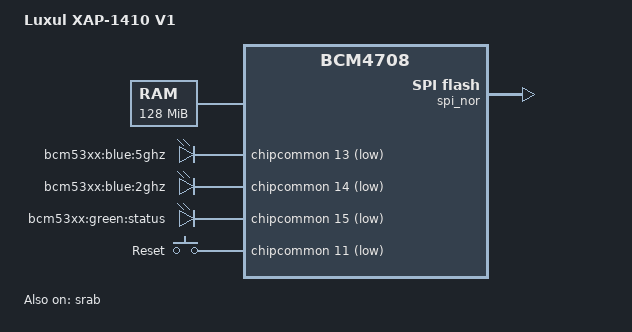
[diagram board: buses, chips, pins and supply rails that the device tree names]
// SPDX-License-Identifier: GPL-2.0-or-later OR MIT
/*
 * Copyright 2017 Luxul Inc.
 */

/dts-v1/;

#include "bcm47081.dtsi"

/ {
	compatible = "luxul,xap-1410-v1", "brcm,bcm47081", "brcm,bcm4708";
	model = "Luxul XAP-1410 V1";

	chosen {
		bootargs = "console=ttyS0,115200";
	};

	memory@0 {
		device_type = "memory";
		reg = <0x00000000 0x08000000>;
	};

	nvram@1eff0000 {
		compatible = "brcm,nvram";
		reg = <0x1eff0000 0x10000>;

		et0macaddr: et0macaddr {
		};
	};

	leds {
		compatible = "gpio-leds";

		led-5ghz {
			label = "bcm53xx:blue:5ghz";
			gpios = <&chipcommon 13 GPIO_ACTIVE_LOW>;
			linux,default-trigger = "none";
		};

		led-2ghz {
			label = "bcm53xx:blue:2ghz";
			gpios = <&chipcommon 14 GPIO_ACTIVE_LOW>;
			linux,default-trigger = "none";
		};

		led-status {
			label = "bcm53xx:green:status";
			gpios = <&chipcommon 15 GPIO_ACTIVE_LOW>;
			linux,default-trigger = "timer";
		};
	};

	gpio-keys {
		compatible = "gpio-keys";

		button-restart {
			label = "Reset";
			linux,code = <KEY_RESTART>;
			gpios = <&chipcommon 11 GPIO_ACTIVE_LOW>;
		};
	};
};

&gmac0 {
	nvmem-cells = <&et0macaddr>;
	nvmem-cell-names = "mac-address";
};

&spi_nor {
	status = "okay";
};

&srab {
	status = "okay";

	ports {
		port@4 {
			label = "poe";
		};

		port@5 {
			label = "cpu";
		};
	};
};
